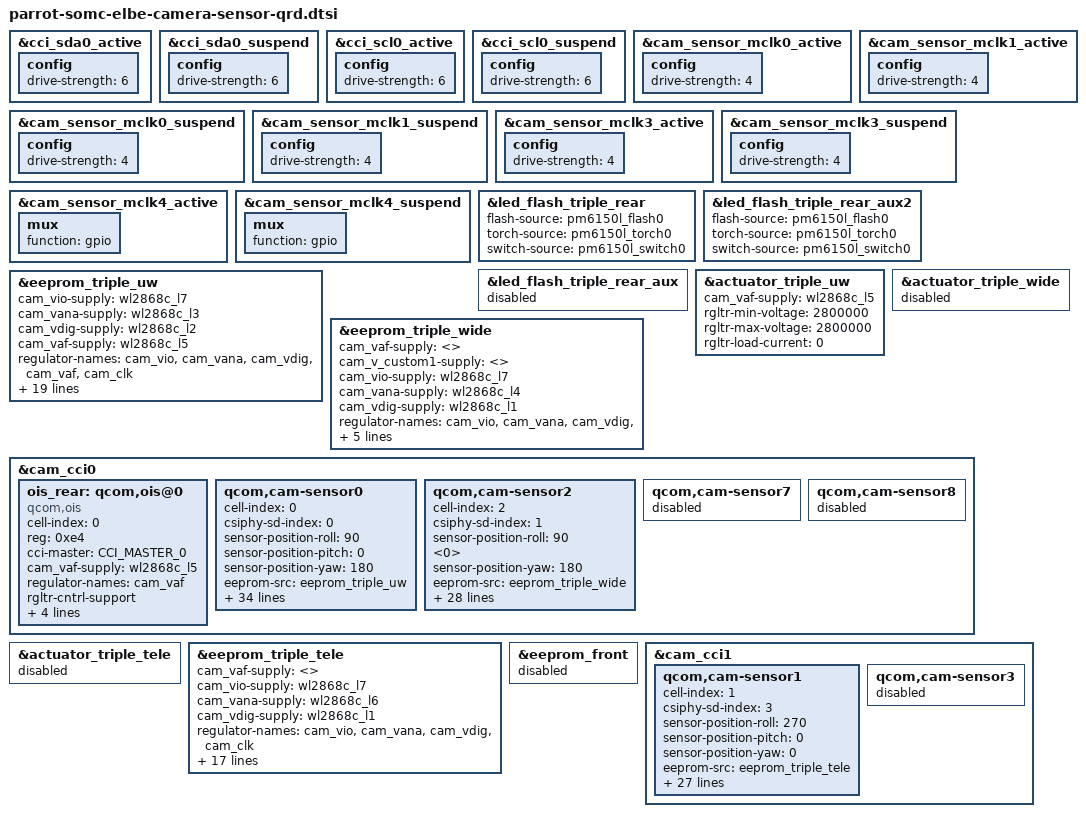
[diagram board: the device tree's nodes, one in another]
&cci_sda0_active {
	config {
		drive-strength = <6>;
	};
};

&cci_sda0_suspend {
	config {
		drive-strength = <6>;
	};
};

&cci_scl0_active {
	config {
		drive-strength = <6>;
	};
};

&cci_scl0_suspend {
	config {
		drive-strength = <6>;
	};
};

&cam_sensor_mclk0_active {
	config {
		drive-strength = <4>;
	};
};

&cam_sensor_mclk0_suspend {
	config {
		drive-strength = <4>;
	};
};

&cam_sensor_mclk1_active {
	config {
		drive-strength = <4>;
	};
};

&cam_sensor_mclk1_suspend {
	config {
		drive-strength = <4>;
	};
};

&cam_sensor_mclk3_active {
	config {
		drive-strength = <4>;
	};
};

&cam_sensor_mclk3_suspend {
	config {
		drive-strength = <4>;
	};
};

&cam_sensor_mclk4_active {
	mux {
		function = "gpio";
	};
};

&cam_sensor_mclk4_suspend {
	mux {
		function = "gpio";
	};
};

&led_flash_triple_rear {
	flash-source = <&pm6150l_flash0>;
	torch-source = <&pm6150l_torch0>;
	switch-source = <&pm6150l_switch0>;
};

&led_flash_triple_rear_aux2 {
	flash-source = <&pm6150l_flash0>;
	torch-source = <&pm6150l_torch0>;
	switch-source = <&pm6150l_switch0>;
};

&led_flash_triple_rear_aux {
	status = "disabled";
};

&actuator_triple_uw {
	cam_vaf-supply = <&wl2868c_l5>;
	rgltr-min-voltage = <2800000>;
	rgltr-max-voltage = <2800000>;
	rgltr-load-current = <0>;
	status = "ok";
};

&actuator_triple_wide {
	status = "disabled";
};

&eeprom_triple_uw {
	cam_vio-supply  = <&wl2868c_l7>;
	cam_vana-supply = <&wl2868c_l3>;
	cam_vdig-supply = <&wl2868c_l2>;
	cam_vaf-supply  = <&wl2868c_l5>;
	regulator-names = "cam_vio", "cam_vana", "cam_vdig",
			  "cam_vaf", "cam_clk";
	rgltr-cntrl-support;
	rgltr-min-voltage  = <1800000 2800000 1100000 2800000 0>;
	rgltr-max-voltage  = <1800000 2800000 1100000 2800000 0>;
	rgltr-load-current = <0 0 0 0 0>;
	pinctrl-0 = <&cam_sensor_mclk0_active
		     &cam_sensor_active_rst0
		     &cam_sensor_mclk4_active>;
	pinctrl-1 = <&cam_sensor_mclk0_suspend
		     &cam_sensor_suspend_rst0
		     &cam_sensor_mclk4_suspend>;
	gpios = <&tlmm 39 0>,
		<&tlmm 44 0>,
		<&tlmm 43 0>;
	gpio-reset = <1>;
	gpio-standby = <2>;
	gpio-req-tbl-num = <0 1 2>;
	gpio-req-tbl-flags = <1 0 0>;
	gpio-req-tbl-label = "CAMIF_MCLK0",
			     "CAM_RESET0",
			     "OIS_VDD";
	status = "ok";
};

&eeprom_triple_wide {
	cam_vaf-supply = <>;
	cam_v_custom1-supply = <>;
	cam_vio-supply  = <&wl2868c_l7>;
	cam_vana-supply = <&wl2868c_l4>;
	cam_vdig-supply = <&wl2868c_l1>;
	regulator-names = "cam_vio", "cam_vana", "cam_vdig", "cam_clk";
	rgltr-cntrl-support;
	rgltr-min-voltage  = <1800000 2800000 1200000 0>;
	rgltr-max-voltage  = <1800000 2800000 1200000 0>;
	rgltr-load-current = <0 0 0 0>;
	status = "ok";
};

&cam_cci0 {
	ois_rear: qcom,ois@0 {
		cell-index = <0>;
		reg = <0xe4>;
		compatible = "qcom,ois";
		cci-master = <CCI_MASTER_0>;
		cam_vaf-supply = <&wl2868c_l5>;
		regulator-names = "cam_vaf";
		rgltr-cntrl-support;
		pwm-switch;
		rgltr-min-voltage = <2800000>;
		rgltr-max-voltage = <2800000>;
		rgltr-load-current = <0>;
		status = "ok";
	};

	qcom,cam-sensor0 {
		cell-index = <0>;
		csiphy-sd-index = <0>;
		sensor-position-roll = <90>;
		sensor-position-pitch = <0>;
		sensor-position-yaw = <180>;
		eeprom-src = <&eeprom_triple_uw>;
		actuator-src = <&actuator_triple_uw>;
		led-flash-src = <&led_flash_triple_rear>;
		ois-src = <&ois_rear>;
		cam_bob-supply = <>;
		cam_vio-supply  = <&wl2868c_l7>;
		cam_vana-supply = <&wl2868c_l3>;
		cam_vdig-supply = <&wl2868c_l2>;
		cam_vaf-supply  = <&wl2868c_l5>;
		cam_clk-supply  = <&cam_cc_camss_top_gdsc>;
		regulator-names = "cam_vio", "cam_vana", "cam_vdig",
				  "cam_vaf", "cam_clk";
		rgltr-cntrl-support;
		rgltr-min-voltage  = <1800000 2800000 1100000 2800000 0>;
		rgltr-max-voltage  = <1800000 2800000 1100000 2800000 0>;
		rgltr-load-current = <0 0 0 0 0>;
		pinctrl-0 = <&cam_sensor_mclk0_active
			     &cam_sensor_active_rst0
			     &cam_sensor_mclk4_active>;
		pinctrl-1 = <&cam_sensor_mclk0_suspend
			     &cam_sensor_suspend_rst0
			     &cam_sensor_mclk4_suspend>;
		gpios = <&tlmm 39 0>,
			<&tlmm 44 0>,
			<&tlmm 43 0>;
		gpio-reset = <1>;
		gpio-standby = <2>;
		gpio-req-tbl-num = <0 1 2>;
		gpio-req-tbl-flags = <1 0 0>;
		gpio-req-tbl-label = "CAMIF_MCLK0",
				     "CAM_RESET0",
				     "OIS_VDD";
		cci-master = <CCI_MASTER_0>;
		clocks = <&camcc CAM_CC_MCLK0_CLK>;
		clock-names = "cam_clk";
		clock-cntl-level = "nominal";
		clock-rates = <24000000>;
		status = "ok";
	};

	qcom,cam-sensor2 {
		cell-index = <2>;
		csiphy-sd-index = <1>;
		sensor-position-roll = <90>;
		sensor-position-pitch  <0>;
		sensor-position-yaw = <180>;
		eeprom-src = <&eeprom_triple_wide>;
		led-flash-src  <&led_flash_triple_rear_aux2>;
		actuator-src = <>;
		cam_bob-supply = <>;
		cam_vaf-supply = <>;
		cam_v_custom1-supply = <>;
		cam_vio-supply = <&wl2868c_l7>;
		cam_vana-supply = <&wl2868c_l4>;
		cam_vdig-supply = <&wl2868c_l1>;
		cam_clk-supply = <&cam_cc_camss_top_gdsc>;
		regulator-names = "cam_vio", "cam_vana", "cam_vdig", "cam_clk";
		rgltr-cntrl-support;
		rgltr-min-voltage  = <1800000 2800000 1200000 0>;
		rgltr-max-voltage  = <1800000 2800000 1200000 0>;
		rgltr-load-current = <0 0 0 0>;
		pinctrl-0 = <&cam_sensor_mclk1_active  &cam_sensor_active_rst1>;
		pinctrl-1 = <&cam_sensor_mclk1_suspend &cam_sensor_suspend_rst1>;
		gpios = <&tlmm 40 0>,
			<&tlmm 45 0>;
		gpio-reset = <1>;
		gpio-req-tbl-num = <0 1>;
		gpio-req-tbl-flags = <1 0>;
		gpio-req-tbl-label = "CAMIF_MCLK1", "CAM_RESET1";
		cci-master = <CCI_MASTER_1>;
		clocks = <&camcc CAM_CC_MCLK1_CLK>;
		clock-names = "cam_clk";
		clock-cntl-level = "nominal";
		clock-rates = <24000000>;
		status = "ok";
	};

	qcom,cam-sensor7 {
		status = "disabled";
	};

	qcom,cam-sensor8 {
		status = "disabled";
	};
};

&actuator_triple_tele {
	status = "disabled";
};

&eeprom_triple_tele {
	cam_vaf-supply = <>;
	cam_vio-supply  = <&wl2868c_l7>;
	cam_vana-supply = <&wl2868c_l6>;
	cam_vdig-supply = <&wl2868c_l1>;
	regulator-names = "cam_vio", "cam_vana", "cam_vdig", "cam_clk";
	rgltr-cntrl-support;
	rgltr-min-voltage  = <1800000 2800000 1200000 0>;
	rgltr-max-voltage  = <1800000 2800000 1200000 0>;
	rgltr-load-current = <0 0 0 0>;
	pinctrl-0 = <&cam_sensor_mclk3_active  &cam_sensor_active_rst3>;
	pinctrl-1 = <&cam_sensor_mclk3_suspend &cam_sensor_suspend_rst3>;
	gpios = <&tlmm 42 0>,
		<&tlmm 47 0>;
	gpio-reset = <1>;
	gpio-req-tbl-num = <0 1>;
	gpio-req-tbl-flags = <1 0>;
	gpio-req-tbl-label = "CAMIF_MCLK3", "CAM_RESET3";
	cci-master = <CCI_MASTER_1>;
	clocks = <&camcc CAM_CC_MCLK3_CLK>;
	clock-names = "cam_clk";
	clock-cntl-level = "nominal";
	clock-rates = <19200000>;
	status = "ok";
};

&eeprom_front {
	status = "disabled";
};

&cam_cci1 {
	qcom,cam-sensor1 {
		cell-index = <1>;
		csiphy-sd-index = <3>;
		sensor-position-roll  = <270>;
		sensor-position-pitch = <0>;
		sensor-position-yaw = <0>;
		eeprom-src = <&eeprom_triple_tele>;
		led-flash-src = <>;
		actuator-src  = <>;
		cam_bob-supply = <>;
		cam_vaf-supply = <>;
		cam_vio-supply  = <&wl2868c_l7>;
		cam_vana-supply = <&wl2868c_l6>;
		cam_vdig-supply = <&wl2868c_l1>;
		cam_clk-supply  = <&cam_cc_camss_top_gdsc>;
		regulator-names = "cam_vio", "cam_vana", "cam_vdig", "cam_clk";
		rgltr-cntrl-support;
		rgltr-min-voltage  = <1800000 2800000 1200000 0>;
		rgltr-max-voltage  = <1800000 2800000 1200000 0>;
		rgltr-load-current = <0 0 0 0>;
		pinctrl-0 = <&cam_sensor_mclk3_active  &cam_sensor_active_rst3>;
		pinctrl-1 = <&cam_sensor_mclk3_suspend &cam_sensor_suspend_rst3>;
		gpios = <&tlmm 42 0>,
			<&tlmm 47 0>;
		gpio-reset = <1>;
		gpio-req-tbl-num = <0 1>;
		gpio-req-tbl-flags = <1 0>;
		gpio-req-tbl-label = "CAMIF_MCLK3", "CAM_RESET3";
		cci-master = <CCI_MASTER_1>;
		clocks = <&camcc CAM_CC_MCLK3_CLK>;
		clock-names = "cam_clk";
		clock-cntl-level = "nominal";
		clock-rates = <19200000>;
		status = "ok";
	};

	qcom,cam-sensor3 {
		status = "disabled";
	};
};
